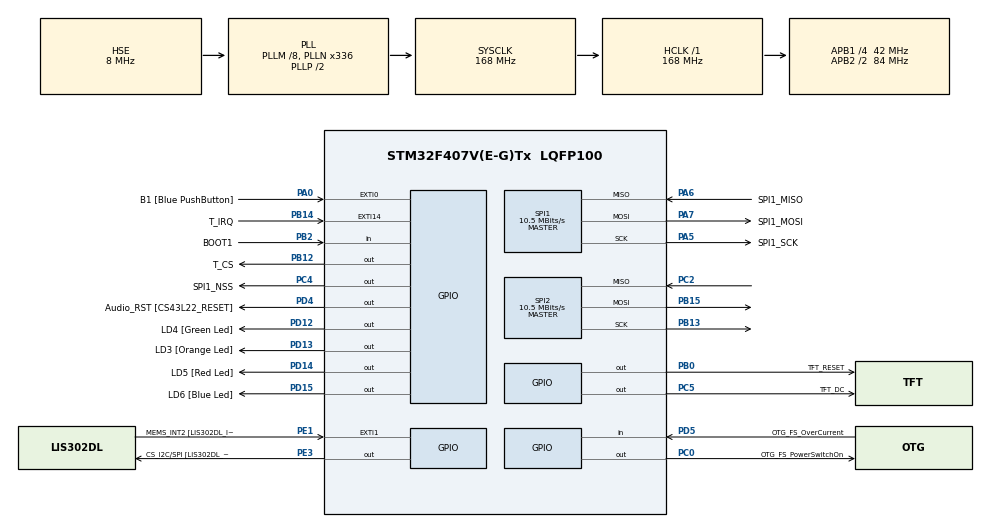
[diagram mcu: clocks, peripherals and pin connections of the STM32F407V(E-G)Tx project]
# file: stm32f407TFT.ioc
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Dma.Request0=SPI1_TX
Dma.SPI1_TX.0.Direction=DMA_MEMORY_TO_PERIPH
Dma.SPI1_TX.0.FIFOMode=DMA_FIFOMODE_ENABLE
Dma.SPI1_TX.0.FIFOThreshold=DMA_FIFO_THRESHOLD_FULL
Dma.SPI1_TX.0.Instance=DMA2_Stream3
Dma.SPI1_TX.0.MemBurst=DMA_MBURST_SINGLE
Dma.SPI1_TX.0.MemDataAlignment=DMA_MDATAALIGN_BYTE
Dma.SPI1_TX.0.MemInc=DMA_MINC_ENABLE
Dma.SPI1_TX.0.Mode=DMA_NORMAL
Dma.SPI1_TX.0.PeriphBurst=DMA_PBURST_SINGLE
Dma.SPI1_TX.0.PeriphDataAlignment=DMA_PDATAALIGN_BYTE
Dma.SPI1_TX.0.PeriphInc=DMA_PINC_DISABLE
Dma.SPI1_TX.0.Priority=DMA_PRIORITY_LOW
Mcu.Family=STM32F4
Mcu.Name=STM32F407V(E-G)Tx
Mcu.Package=LQFP100
NVIC.DMA2_Stream3_IRQn=true\:0\:0\:false\:false\:true\:false\:true\:true
NVIC.PriorityGroup=NVIC_PRIORITYGROUP_0
NVIC.TIM2_IRQn=true\:0\:0\:false\:false\:true\:true\:true\:true
PA0-WKUP.GPIO_Label=B1 [Blue PushButton]
PA0-WKUP.GPIO_ModeDefaultEXTI=GPIO_MODE_EVT_RISING
PA0-WKUP.GPIO_PuPd=GPIO_NOPULL
PA0-WKUP.Signal=GPXTI0
PA13.GPIO_Label=SWDIO
PA13.Mode=Trace_Asynchronous_SW
PA13.Signal=SYS_JTMS-SWDIO
PA14.GPIO_Label=SWCLK
PA14.Mode=Trace_Asynchronous_SW
PA14.Signal=SYS_JTCK-SWCLK
PA5.GPIO_Label=SPI1_SCK
PA5.GPIO_Mode=GPIO_MODE_AF_PP
PA5.GPIO_PuPd=GPIO_NOPULL
PA5.GPIO_Speed=GPIO_SPEED_FREQ_LOW
PA5.Mode=Full_Duplex_Master
PA5.Signal=SPI1_SCK
PA6.GPIO_Label=SPI1_MISO
PA6.GPIO_Mode=GPIO_MODE_AF_PP
PA6.GPIO_PuPd=GPIO_NOPULL
PA6.GPIO_Speed=GPIO_SPEED_FREQ_LOW
PA6.Mode=Full_Duplex_Master
PA6.Signal=SPI1_MISO
PA7.GPIO_Label=SPI1_MOSI
PA7.GPIO_Mode=GPIO_MODE_AF_PP
PA7.GPIO_PuPd=GPIO_NOPULL
PA7.GPIO_Speed=GPIO_SPEED_FREQ_LOW
PA7.Mode=Full_Duplex_Master
PA7.Signal=SPI1_MOSI
PB0.GPIO_Label=TFT_RESET
PB0.Signal=GPIO_Output
PB12.GPIO_Label=T_CS
PB12.Signal=GPIO_Output
PB13.Mode=Full_Duplex_Master
PB13.Signal=SPI2_SCK
PB14.GPIO_Label=T_IRQ
PB14.Signal=GPXTI14
PB15.Mode=Full_Duplex_Master
PB15.Signal=SPI2_MOSI
PB2.GPIO_Label=BOOT1
PB2.GPIO_Mode=GPIO_MODE_INPUT
PB2.GPIO_PuPd=GPIO_NOPULL
PB2.Signal=GPIO_Input
PB3.GPIO_Label=SWO
PB3.Mode=Trace_Asynchronous_SW
PB3.Signal=SYS_JTDO-SWO
PB6.GPIO_Label=Audio_SCL [CS43L22_SCL]
PB6.GPIO_Mode=GPIO_MODE_AF_OD
PB6.GPIO_Pu=GPIO_PULLUP
PB6.GPIO_PuPd=GPIO_NOPULL
PB6.GPIO_Speed=GPIO_SPEED_FREQ_LOW
PB6.Signal=I2C1_SCL
PB9.GPIO_Label=Audio_SDA [CS43L22_SDA]
PB9.GPIO_Mode=GPIO_MODE_AF_OD
PB9.GPIO_Pu=GPIO_PULLUP
PB9.GPIO_PuPd=GPIO_NOPULL
PB9.GPIO_Speed=GPIO_SPEED_FREQ_LOW
PB9.Signal=I2C1_SDA
PC0.GPIO_Label=OTG_FS_PowerSwitchOn
PC0.GPIO_PuPd=GPIO_NOPULL
PC0.GPIO_Speed=GPIO_SPEED_FREQ_LOW
PC0.PinState=GPIO_PIN_SET
PC0.Signal=GPIO_Output
PC14-OSC32_IN.GPIO_Label=PC14-OSC32_IN
PC14-OSC32_IN.Mode=LSE-External-Oscillator
PC14-OSC32_IN.Signal=RCC_OSC32_IN
PC15-OSC32_OUT.GPIO_Label=PC15-OSC32_OUT
PC15-OSC32_OUT.Mode=LSE-External-Oscillator
PC15-OSC32_OUT.Signal=RCC_OSC32_OUT
PC2.Mode=Full_Duplex_Master
PC2.Signal=SPI2_MISO
PC4.GPIO_Label=SPI1_NSS
PC4.Signal=GPIO_Output
PC5.GPIO_Label=TFT_DC
PC5.Signal=GPIO_Output
PD12.GPIO_Label=LD4 [Green Led]
PD12.GPIO_PuPd=GPIO_NOPULL
PD12.GPIO_Speed=GPIO_SPEED_FREQ_LOW
PD12.Signal=GPIO_Output
PD13.GPIO_Label=LD3 [Orange Led]
PD13.GPIO_PuPd=GPIO_NOPULL
PD13.GPIO_Speed=GPIO_SPEED_FREQ_LOW
PD13.Signal=GPIO_Output
PD14.GPIO_Label=LD5 [Red Led]
PD14.GPIO_PuPd=GPIO_NOPULL
PD14.GPIO_Speed=GPIO_SPEED_FREQ_LOW
PD14.Signal=GPIO_Output
PD15.GPIO_Label=LD6 [Blue Led]
PD15.GPIO_PuPd=GPIO_NOPULL
PD15.GPIO_Speed=GPIO_SPEED_FREQ_LOW
PD15.Signal=GPIO_Output
PD4.GPIO_Label=Audio_RST [CS43L22_RESET]
PD4.GPIO_PuPd=GPIO_NOPULL
PD4.GPIO_Speed=GPIO_SPEED_FREQ_LOW
PD4.Signal=GPIO_Output
PD5.GPIO_Label=OTG_FS_OverCurrent
PD5.GPIO_Mode=GPIO_MODE_INPUT
PD5.GPIO_PuPd=GPIO_NOPULL
PD5.Signal=GPIO_Input
PE1.GPIO_Label=MEMS_INT2 [LIS302DL_INT2]
PE1.GPIO_ModeDefaultEXTI=GPIO_MODE_EVT_RISING
PE1.GPIO_PuPd=GPIO_NOPULL
PE1.Signal=GPXTI1
PE3.GPIO_Label=CS_I2C/SPI [LIS302DL_CS_I2C/SPI]
PE3.GPIO_PuPd=GPIO_NOPULL
PE3.GPIO_Speed=GPIO_SPEED_FREQ_LOW
PE3.Signal=GPIO_Output
PH0-OSC_IN.GPIO_Label=PH0-OSC_IN
PH0-OSC_IN.Mode=HSE-External-Oscillator
PH0-OSC_IN.Signal=RCC_OSC_IN
PH1-OSC_OUT.GPIO_Label=PH1-OSC_OUT
PH1-OSC_OUT.Mode=HSE-External-Oscillator
PH1-OSC_OUT.Signal=RCC_OSC_OUT
ProjectManager.HeapSize=0x200
ProjectManager.StackSize=0x400
ProjectManager.TargetToolchain=STM32CubeIDE
RCC.48MHZClocksFreq_Value=48000000
RCC.AHBFreq_Value=168000000
RCC.APB1CLKDivider=RCC_HCLK_DIV4
RCC.APB1Freq_Value=42000000
RCC.APB1TimFreq_Value=84000000
RCC.APB2CLKDivider=RCC_HCLK_DIV2
RCC.APB2Freq_Value=84000000
RCC.APB2TimFreq_Value=168000000
RCC.CortexFreq_Value=168000000
RCC.HCLKFreq_Value=168000000
RCC.HSE_VALUE=8000000
RCC.HSI_VALUE=16000000
RCC.PLLM=8
RCC.PLLN=336
RCC.PLLQ=7
RCC.PLLSourceVirtual=RCC_PLLSOURCE_HSE
RCC.SYSCLKFreq_VALUE=168000000
RCC.SYSCLKSource=RCC_SYSCLKSOURCE_PLLCLK
RCC.VCOOutputFreq_Value=336000000
SPI1.BaudRatePrescaler=SPI_BAUDRATEPRESCALER_8
SPI1.BaudRatePrescaler-Full_Duplex_Master=SPI_BAUDRATEPRESCALER_2
SPI1.CalculateBaudRate=10.5 MBits/s
SPI1.CalculateBaudRate-Full_Duplex_Master=42.0 MBits/s
SPI1.Direction=SPI_DIRECTION_2LINES
SPI1.Mode=SPI_MODE_MASTER
SPI1.Mode-Full_Duplex_Master=SPI_MODE_MASTER
SPI1.VirtualType=VM_MASTER
SPI2.BaudRatePrescaler=SPI_BAUDRATEPRESCALER_4
SPI2.CalculateBaudRate=10.5 MBits/s
SPI2.Direction=SPI_DIRECTION_2LINES
SPI2.Mode=SPI_MODE_MASTER
SPI2.VirtualType=VM_MASTER
STMicroelectronics.X-CUBE-TOUCHGFX.4.20.0.ApplicationCcGraphicsJjApplication=TouchGFXOoGenerator
STMicroelectronics.X-CUBE-TOUCHGFX.4.20.0.tgfx_buffering_strategy=Partial
STMicroelectronics.X-CUBE-TOUCHGFX.4.20.0.tgfx_custom_height=240
STMicroelectronics.X-CUBE-TOUCHGFX.4.20.0.tgfx_custom_width=320
STMicroelectronics.X-CUBE-TOUCHGFX.4.20.0_IsPackSelfContextualization=true
TIM2.Period=25000-1
TIM2.Prescaler=84-1
VP_CRC_VS_CRC.Mode=CRC_Activate
VP_STMicroelectronics.X-CUBE-TOUCHGFX_VS_GraphicsJjApplication_4.20.0.Mode=GraphicsJjApplication
VP_TIM2_VS_ClockSourceINT.Mode=Internal
board=STM32F407G-DISC1

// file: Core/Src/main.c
/* USER CODE BEGIN Header */
/**
  ******************************************************************************
  * @file           : main.c
  * @brief          : Main program body
  ******************************************************************************
  * @attention
  *
  * Copyright (c) 2022 STMicroelectronics.
  * All rights reserved.
  *
  * This software is licensed under terms that can be found in the LICENSE file
  * in the root directory of this software component.
  * If no LICENSE file comes with this software, it is provided AS-IS.
  *
  ******************************************************************************
  */
/* USER CODE END Header */
#include "main.h"
#include "app_touchgfx.h"

/* USER CODE BEGIN Includes */
#include "ili9341.h"
#include "xpt2046.h"
#include <stdio.h>
/* USER CODE END Includes */

CRC_HandleTypeDef hcrc;

SPI_HandleTypeDef hspi1;
SPI_HandleTypeDef hspi2;
DMA_HandleTypeDef hdma_spi1_tx;

TIM_HandleTypeDef htim2;

void SystemClock_Config(void);
static void MX_GPIO_Init(void);
static void MX_DMA_Init(void);
static void MX_SPI1_Init(void);
static void MX_CRC_Init(void);
static void MX_SPI2_Init(void);
static void MX_TIM2_Init(void);

int main(void)
{

  /* MCU Configuration--------------------------------------------------------*/

  /* Reset of all peripherals, Initializes the Flash interface and the Systick. */
  HAL_Init();

  /* Configure the system clock */
  SystemClock_Config();

  /* Initialize all configured peripherals */
  MX_GPIO_Init();
  MX_DMA_Init();
  MX_SPI1_Init();
  MX_CRC_Init();
  MX_SPI2_Init();
  MX_TIM2_Init();
  MX_TouchGFX_Init();
  /* USER CODE BEGIN 2 */
  HAL_TIM_Base_Start_IT(&htim2);
  ILI9341_Init();
  XPT2046_Init();
  /* USER CODE END 2 */

  /* Infinite loop */
  while (1)
  {

  MX_TouchGFX_Process();
  }
}

void SystemClock_Config(void)
{
  RCC_OscInitTypeDef RCC_OscInitStruct = {0};
  RCC_ClkInitTypeDef RCC_ClkInitStruct = {0};

  /** Configure the main internal regulator output voltage
  */
  __HAL_RCC_PWR_CLK_ENABLE();
  __HAL_PWR_VOLTAGESCALING_CONFIG(PWR_REGULATOR_VOLTAGE_SCALE1);

  /** Initializes the RCC Oscillators according to the specified parameters
  * in the RCC_OscInitTypeDef structure.
  */
  RCC_OscInitStruct.OscillatorType = RCC_OSCILLATORTYPE_HSE;
  RCC_OscInitStruct.HSEState = RCC_HSE_ON;
  RCC_OscInitStruct.PLL.PLLState = RCC_PLL_ON;
  RCC_OscInitStruct.PLL.PLLSource = RCC_PLLSOURCE_HSE;
  RCC_OscInitStruct.PLL.PLLM = 8;
  RCC_OscInitStruct.PLL.PLLN = 336;
  RCC_OscInitStruct.PLL.PLLP = RCC_PLLP_DIV2;
  RCC_OscInitStruct.PLL.PLLQ = 7;
  if (HAL_RCC_OscConfig(&RCC_OscInitStruct) != HAL_OK)
  {
    Error_Handler();
  }

  /** Initializes the CPU, AHB and APB buses clocks
  */
  RCC_ClkInitStruct.ClockType = RCC_CLOCKTYPE_HCLK|RCC_CLOCKTYPE_SYSCLK
                              |RCC_CLOCKTYPE_PCLK1|RCC_CLOCKTYPE_PCLK2;
  RCC_ClkInitStruct.SYSCLKSource = RCC_SYSCLKSOURCE_PLLCLK;
  RCC_ClkInitStruct.AHBCLKDivider = RCC_SYSCLK_DIV1;
  RCC_ClkInitStruct.APB1CLKDivider = RCC_HCLK_DIV4;
  RCC_ClkInitStruct.APB2CLKDivider = RCC_HCLK_DIV2;

  if (HAL_RCC_ClockConfig(&RCC_ClkInitStruct, FLASH_LATENCY_5) != HAL_OK)
  {
    Error_Handler();
  }
}

static void MX_CRC_Init(void)
{

  hcrc.Instance = CRC;
  if (HAL_CRC_Init(&hcrc) != HAL_OK)
  {
    Error_Handler();
  }

}

static void MX_SPI1_Init(void)
{

  /* SPI1 parameter configuration*/
  hspi1.Instance = SPI1;
  hspi1.Init.Mode = SPI_MODE_MASTER;
  hspi1.Init.Direction = SPI_DIRECTION_2LINES;
  hspi1.Init.DataSize = SPI_DATASIZE_8BIT;
  hspi1.Init.CLKPolarity = SPI_POLARITY_LOW;
  hspi1.Init.CLKPhase = SPI_PHASE_1EDGE;
  hspi1.Init.NSS = SPI_NSS_SOFT;
  hspi1.Init.BaudRatePrescaler = SPI_BAUDRATEPRESCALER_8;
  hspi1.Init.FirstBit = SPI_FIRSTBIT_MSB;
  hspi1.Init.TIMode = SPI_TIMODE_DISABLE;
  hspi1.Init.CRCCalculation = SPI_CRCCALCULATION_DISABLE;
  hspi1.Init.CRCPolynomial = 10;
  if (HAL_SPI_Init(&hspi1) != HAL_OK)
  {
    Error_Handler();
  }

}

static void MX_SPI2_Init(void)
{

  /* SPI2 parameter configuration*/
  hspi2.Instance = SPI2;
  hspi2.Init.Mode = SPI_MODE_MASTER;
  hspi2.Init.Direction = SPI_DIRECTION_2LINES;
  hspi2.Init.DataSize = SPI_DATASIZE_8BIT;
  hspi2.Init.CLKPolarity = SPI_POLARITY_LOW;
  hspi2.Init.CLKPhase = SPI_PHASE_1EDGE;
  hspi2.Init.NSS = SPI_NSS_SOFT;
  hspi2.Init.BaudRatePrescaler = SPI_BAUDRATEPRESCALER_4;
  hspi2.Init.FirstBit = SPI_FIRSTBIT_MSB;
  hspi2.Init.TIMode = SPI_TIMODE_DISABLE;
  hspi2.Init.CRCCalculation = SPI_CRCCALCULATION_DISABLE;
  hspi2.Init.CRCPolynomial = 10;
  if (HAL_SPI_Init(&hspi2) != HAL_OK)
  {
    Error_Handler();
  }

}

static void MX_TIM2_Init(void)
{

  TIM_ClockConfigTypeDef sClockSourceConfig = {0};
  TIM_MasterConfigTypeDef sMasterConfig = {0};

  htim2.Instance = TIM2;
  htim2.Init.Prescaler = 84-1;
  htim2.Init.CounterMode = TIM_COUNTERMODE_UP;
  htim2.Init.Period = 25000-1;
  htim2.Init.ClockDivision = TIM_CLOCKDIVISION_DIV1;
  htim2.Init.AutoReloadPreload = TIM_AUTORELOAD_PRELOAD_DISABLE;
  if (HAL_TIM_Base_Init(&htim2) != HAL_OK)
  {
    Error_Handler();
  }
  sClockSourceConfig.ClockSource = TIM_CLOCKSOURCE_INTERNAL;
  if (HAL_TIM_ConfigClockSource(&htim2, &sClockSourceConfig) != HAL_OK)
  {
    Error_Handler();
  }
  sMasterConfig.MasterOutputTrigger = TIM_TRGO_RESET;
  sMasterConfig.MasterSlaveMode = TIM_MASTERSLAVEMODE_DISABLE;
  if (HAL_TIMEx_MasterConfigSynchronization(&htim2, &sMasterConfig) != HAL_OK)
  {
    Error_Handler();
  }

}

static void MX_DMA_Init(void)
{

  /* DMA controller clock enable */
  __HAL_RCC_DMA2_CLK_ENABLE();

  /* DMA interrupt init */
  /* DMA2_Stream3_IRQn interrupt configuration */
  HAL_NVIC_SetPriority(DMA2_Stream3_IRQn, 0, 0);
  HAL_NVIC_EnableIRQ(DMA2_Stream3_IRQn);

}

static void MX_GPIO_Init(void)
{
  GPIO_InitTypeDef GPIO_InitStruct = {0};

  /* GPIO Ports Clock Enable */
  __HAL_RCC_GPIOE_CLK_ENABLE();
  __HAL_RCC_GPIOC_CLK_ENABLE();
  __HAL_RCC_GPIOH_CLK_ENABLE();
  __HAL_RCC_GPIOA_CLK_ENABLE();
  __HAL_RCC_GPIOB_CLK_ENABLE();
  __HAL_RCC_GPIOD_CLK_ENABLE();

  /*Configure GPIO pin Output Level */
  HAL_GPIO_WritePin(CS_I2C_SPI_GPIO_Port, CS_I2C_SPI_Pin, GPIO_PIN_RESET);

  /*Configure GPIO pin Output Level */
  HAL_GPIO_WritePin(OTG_FS_PowerSwitchOn_GPIO_Port, OTG_FS_PowerSwitchOn_Pin, GPIO_PIN_SET);

  /*Configure GPIO pin Output Level */
  HAL_GPIO_WritePin(GPIOC, SPI1_NSS_Pin|TFT_DC_Pin, GPIO_PIN_RESET);

  /*Configure GPIO pin Output Level */
  HAL_GPIO_WritePin(GPIOB, TFT_RESET_Pin|T_CS_Pin, GPIO_PIN_RESET);

  /*Configure GPIO pin Output Level */
  HAL_GPIO_WritePin(GPIOD, LD4_Pin|LD3_Pin|LD5_Pin|LD6_Pin
                          |Audio_RST_Pin, GPIO_PIN_RESET);

  /*Configure GPIO pin : CS_I2C_SPI_Pin */
  GPIO_InitStruct.Pin = CS_I2C_SPI_Pin;
  GPIO_InitStruct.Mode = GPIO_MODE_OUTPUT_PP;
  GPIO_InitStruct.Pull = GPIO_NOPULL;
  GPIO_InitStruct.Speed = GPIO_SPEED_FREQ_LOW;
  HAL_GPIO_Init(CS_I2C_SPI_GPIO_Port, &GPIO_InitStruct);

  /*Configure GPIO pins : OTG_FS_PowerSwitchOn_Pin SPI1_NSS_Pin TFT_DC_Pin */
  GPIO_InitStruct.Pin = OTG_FS_PowerSwitchOn_Pin|SPI1_NSS_Pin|TFT_DC_Pin;
  GPIO_InitStruct.Mode = GPIO_MODE_OUTPUT_PP;
  GPIO_InitStruct.Pull = GPIO_NOPULL;
  GPIO_InitStruct.Speed = GPIO_SPEED_FREQ_LOW;
  HAL_GPIO_Init(GPIOC, &GPIO_InitStruct);

  /*Configure GPIO pin : B1_Pin */
  GPIO_InitStruct.Pin = B1_Pin;
  GPIO_InitStruct.Mode = GPIO_MODE_EVT_RISING;
  GPIO_InitStruct.Pull = GPIO_NOPULL;
  HAL_GPIO_Init(B1_GPIO_Port, &GPIO_InitStruct);

  /*Configure GPIO pins : TFT_RESET_Pin T_CS_Pin */
  GPIO_InitStruct.Pin = TFT_RESET_Pin|T_CS_Pin;
  GPIO_InitStruct.Mode = GPIO_MODE_OUTPUT_PP;
  GPIO_InitStruct.Pull = GPIO_NOPULL;
  GPIO_InitStruct.Speed = GPIO_SPEED_FREQ_LOW;
  HAL_GPIO_Init(GPIOB, &GPIO_InitStruct);

  /*Configure GPIO pin : BOOT1_Pin */
  GPIO_InitStruct.Pin = BOOT1_Pin;
  GPIO_InitStruct.Mode = GPIO_MODE_INPUT;
  GPIO_InitStruct.Pull = GPIO_NOPULL;
  HAL_GPIO_Init(BOOT1_GPIO_Port, &GPIO_InitStruct);

  /*Configure GPIO pin : T_IRQ_Pin */
  GPIO_InitStruct.Pin = T_IRQ_Pin;
  GPIO_InitStruct.Mode = GPIO_MODE_IT_RISING;
  GPIO_InitStruct.Pull = GPIO_NOPULL;
  HAL_GPIO_Init(T_IRQ_GPIO_Port, &GPIO_InitStruct);

  /*Configure GPIO pins : LD4_Pin LD3_Pin LD5_Pin LD6_Pin
                           Audio_RST_Pin */
  GPIO_InitStruct.Pin = LD4_Pin|LD3_Pin|LD5_Pin|LD6_Pin
                          |Audio_RST_Pin;
  GPIO_InitStruct.Mode = GPIO_MODE_OUTPUT_PP;
  GPIO_InitStruct.Pull = GPIO_NOPULL;
  GPIO_InitStruct.Speed = GPIO_SPEED_FREQ_LOW;
  HAL_GPIO_Init(GPIOD, &GPIO_InitStruct);

  /*Configure GPIO pin : OTG_FS_OverCurrent_Pin */
  GPIO_InitStruct.Pin = OTG_FS_OverCurrent_Pin;
  GPIO_InitStruct.Mode = GPIO_MODE_INPUT;
  GPIO_InitStruct.Pull = GPIO_NOPULL;
  HAL_GPIO_Init(OTG_FS_OverCurrent_GPIO_Port, &GPIO_InitStruct);

  /*Configure GPIO pins : Audio_SCL_Pin Audio_SDA_Pin */
  GPIO_InitStruct.Pin = Audio_SCL_Pin|Audio_SDA_Pin;
  GPIO_InitStruct.Mode = GPIO_MODE_AF_OD;
  GPIO_InitStruct.Pull = GPIO_PULLUP;
  GPIO_InitStruct.Speed = GPIO_SPEED_FREQ_LOW;
  GPIO_InitStruct.Alternate = GPIO_AF4_I2C1;
  HAL_GPIO_Init(GPIOB, &GPIO_InitStruct);

  /*Configure GPIO pin : MEMS_INT2_Pin */
  GPIO_InitStruct.Pin = MEMS_INT2_Pin;
  GPIO_InitStruct.Mode = GPIO_MODE_EVT_RISING;
  GPIO_InitStruct.Pull = GPIO_NOPULL;
  HAL_GPIO_Init(MEMS_INT2_GPIO_Port, &GPIO_InitStruct);

}

/* USER CODE BEGIN 4 */
extern void touchgfxSignalVSync(void);

void HAL_TIM_PeriodElapsedCallback(TIM_HandleTypeDef *htim)
{
	if(htim -> Instance == TIM2){
		touchgfxSignalVSync();
	}
}
/* USER CODE END 4 */

void Error_Handler(void)
{
  __disable_irq();
  while (1)
  {
  }
}
